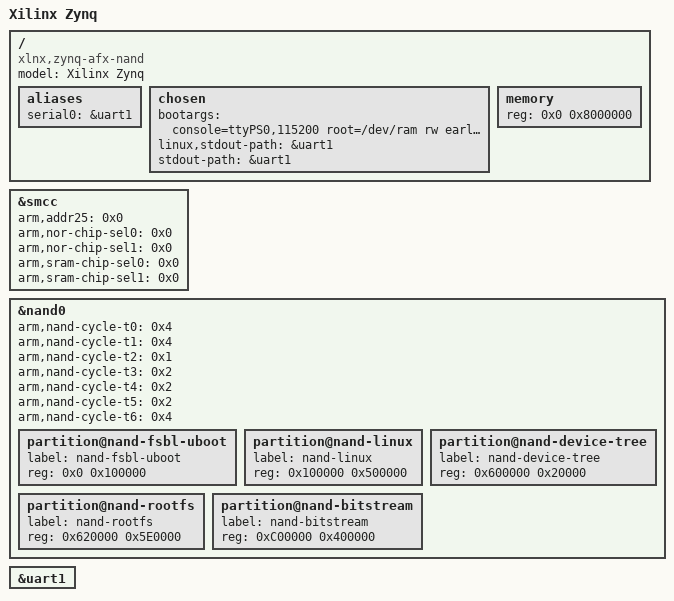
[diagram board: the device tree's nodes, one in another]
/*
 * Device Tree Generator version: 1.1
 *
 * (C) Copyright 2007-2013 Xilinx, Inc.
 * (C) Copyright 2007-2013 Michal Simek
 * (C) Copyright 2007-2012 PetaLogix Qld Pty Ltd
 *
 * Michal SIMEK <monstr@monstr.eu>
 *
 * CAUTION: This file is automatically generated by libgen.
 * Version: Xilinx EDK 14.5 EDK_P.58f
 *
 */
/dts-v1/;
/include/ "zynq-7000.dtsi"

/ {
	compatible = "xlnx,zynq-afx-nand", "xlnx,zynq-7000";
	model = "Xilinx Zynq";

	aliases {
		serial0 = &uart1;
	};

	chosen {
		bootargs = "console=ttyPS0,115200 root=/dev/ram rw earlyprintk";
		linux,stdout-path = &uart1;
		stdout-path = &uart1;
	};

	memory {
		device_type = "memory";
		reg = <0x0 0x8000000>;
	};
};

&smcc {
	status = "okay";
	arm,addr25 = <0x0>;
	arm,nor-chip-sel0 = <0x0>;
	arm,nor-chip-sel1 = <0x0>;
	arm,sram-chip-sel0 = <0x0>;
	arm,sram-chip-sel1 = <0x0>;
};

&nand0 {
	status = "okay";
	arm,nand-cycle-t0 = <0x4>;
	arm,nand-cycle-t1 = <0x4>;
	arm,nand-cycle-t2 = <0x1>;
	arm,nand-cycle-t3 = <0x2>;
	arm,nand-cycle-t4 = <0x2>;
	arm,nand-cycle-t5 = <0x2>;
	arm,nand-cycle-t6 = <0x4>;
	partition@nand-fsbl-uboot {
		label = "nand-fsbl-uboot";
		reg = <0x0 0x100000>;
	};
	partition@nand-linux {
		label = "nand-linux";
		reg = <0x100000 0x500000>;
	};
	partition@nand-device-tree {
		label = "nand-device-tree";
		reg = <0x600000 0x20000>;
	};
	partition@nand-rootfs {
		label = "nand-rootfs";
		reg = <0x620000 0x5E0000>;
	};
	partition@nand-bitstream {
		label = "nand-bitstream";
		reg = <0xC00000 0x400000>;
	};
};

&uart1 {
	status = "okay";
};
